NS_ :

BS_:

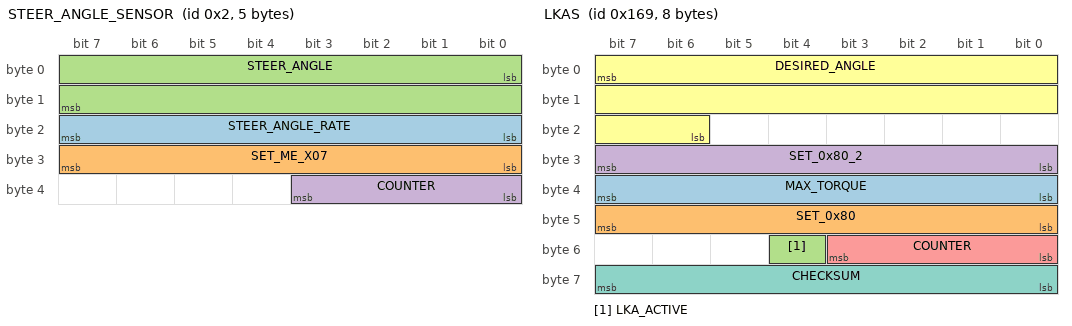
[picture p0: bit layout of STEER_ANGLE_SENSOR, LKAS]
BO_ 2 STEER_ANGLE_SENSOR: 5 XXX
 SG_ STEER_ANGLE_RATE : 16|8@1+ (1,0) [0|255] "" XXX
 SG_ SET_ME_X07 : 24|8@1+ (1,0) [0|255] "" XXX
 SG_ STEER_ANGLE : 0|16@1- (-0.1,0) [0|65535] "" XXX
 SG_ COUNTER : 32|4@1+ (1,0) [0|15] "" XXX

BO_ 361 LKAS: 8 XXX
 SG_ MAX_TORQUE : 39|8@0+ (0.01,0) [0|255] "Nm" XXX
 SG_ SET_0x80 : 47|8@0+ (1,0) [0|255] "" XXX
 SG_ LKA_ACTIVE : 52|1@0+ (1,0) [0|15] "" XXX
 SG_ SET_0x80_2 : 31|8@0+ (1,0) [0|255] "" XXX
 SG_ COUNTER : 51|4@0+ (1,0) [0|15] "" XXX
 SG_ DESIRED_ANGLE : 7|18@0+ (-0.01,1310) [-1311.43|1310] "" XXX
 SG_ CHECKSUM : 63|8@0+ (1,0) [0|255] "" XXX

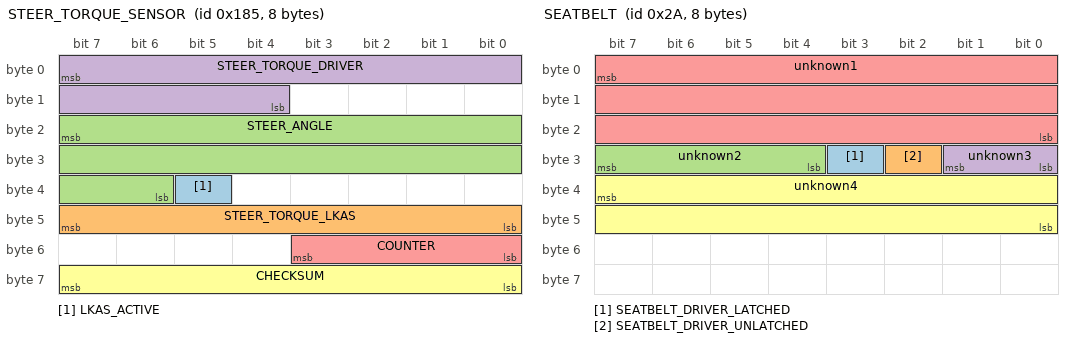
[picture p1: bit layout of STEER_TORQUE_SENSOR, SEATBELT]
BO_ 389 STEER_TORQUE_SENSOR: 8 XXX
 SG_ LKAS_ACTIVE : 37|1@0+ (1,0) [0|3] "" XXX
 SG_ STEER_TORQUE_LKAS : 47|8@0+ (1,0) [0|255] "" XXX
 SG_ STEER_ANGLE : 23|18@0+ (-0.01,1310) [0|262143] "" XXX
 SG_ STEER_TORQUE_DRIVER : 7|12@0+ (-0.01,20.47) [0|4095] "Nm" XXX
 SG_ COUNTER : 51|4@0+ (1,0) [0|15] "" XXX
 SG_ CHECKSUM : 63|8@0+ (1,0) [0|127] "" XXX

BO_ 645 WHEEL_SPEEDS_REAR: 8 XXX
 SG_ WHEEL_SPEED_RR : 7|16@0+ (0.005,0) [0|65535] "KPH" XXX
 SG_ WHEEL_SPEED_RL : 23|16@0+ (0.005,0) [0|65535] "KPH" XXX

BO_ 689 PROPILOT_HUD: 8 XXX
 SG_ LARGE_WARNING_FLASHING : 9|1@0+ (1,0) [0|1] "" XXX
 SG_ SIDE_RADAR_ERROR_FLASHING1 : 10|1@0+ (1,0) [0|1] "" XXX
 SG_ SIDE_RADAR_ERROR_FLASHING2 : 11|1@0+ (1,0) [0|1] "" XXX
 SG_ RIGHT_LANE_YELLOW_FLASH : 12|1@0+ (1,0) [0|1] "" XXX
 SG_ LEFT_LANE_YELLOW_FLASH : 13|1@0+ (1,0) [0|1] "" XXX
 SG_ LEAD_CAR : 14|1@0+ (1,0) [0|1] "" XXX
 SG_ LEAD_CAR_ERROR : 15|1@0+ (1,0) [0|1] "" XXX
 SG_ FRONT_RADAR_ERROR : 16|1@0+ (1,0) [0|1] "" XXX
 SG_ FRONT_RADAR_ERROR_FLASHING : 17|1@0+ (1,0) [0|1] "" XXX
 SG_ RIGHT_LANE_GREEN : 24|1@0+ (1,0) [0|1] "" XXX
 SG_ LEFT_LANE_GREEN : 25|1@0+ (1,0) [0|1] "" XXX
 SG_ SIDE_RADAR_ERROR_FLASHING3 : 27|1@0+ (1,0) [0|1] "" XXX
 SG_ LKAS_ERROR_FLASHING : 29|1@0+ (1,0) [0|1] "" XXX
 SG_ SAFETY_SHIELD_ACTIVE : 44|1@0+ (1,0) [0|1] "" XXX
 SG_ LARGE_STEERING_WHEEL_ICON : 61|2@0+ (1,0) [0|3] "" XXX
 SG_ RIGHT_LANE_GREEN_FLASH : 62|1@0+ (1,0) [0|1] "" XXX
 SG_ LEFT_LANE_GREEN_FLASH : 63|1@0+ (1,0) [0|1] "" XXX
 SG_ FOLLOW_DISTANCE : 3|2@0+ (1,0) [0|3] "" XXX
 SG_ AUDIBLE_TONE : 47|3@0+ (1,0) [0|8] "" XXX
 SG_ SPEED_SET_ICON : 7|2@0+ (1,0) [0|3] "" XXX
 SG_ SMALL_STEERING_WHEEL_ICON : 42|3@0+ (1,0) [0|7] "" XXX
 SG_ SET_SPEED : 39|8@0+ (1,0) [0|255] "" XXX
 SG_ unknown02 : 1|2@0+ (1,0) [0|3] "" XXX
 SG_ unknown05 : 5|2@0+ (1,0) [0|3] "" XXX
 SG_ unknown08 : 8|7@0+ (1,0) [0|63] "" XXX
 SG_ unknown26 : 26|1@0+ (1,0) [0|1] "" XXX
 SG_ unknown28 : 28|1@0+ (1,0) [0|1] "" XXX
 SG_ unknown31 : 31|2@0+ (1,0) [0|3] "" XXX
 SG_ unknown43 : 43|1@0+ (1,0) [0|1] "" XXX
 SG_ unknown55 : 55|8@0+ (1,0) [0|63] "" XXX
 SG_ unknown59 : 59|4@0+ (1,0) [0|15] "" XXX

BO_ 783 CRUISE_STATE: 3 XXX
 SG_ CRUISE_ENABLED : 3|1@0+ (1,0) [0|1] "" XXX

BO_ 1228 PROPILOT_HUD_INFO_MSG: 8 XXX
 SG_ NA_HIGH_ACCEL_TEMP : 0|1@0+ (1,0) [0|1] "" XXX
 SG_ SIDE_RADAR_NA_HIGH_CABIN_TEMP : 8|1@0+ (1,0) [0|1] "" XXX
 SG_ SIDE_RADAR_MALFUNCTION : 11|1@0+ (1,0) [0|1] "" XXX
 SG_ LKAS_MALFUNCTION : 12|1@0+ (1,0) [0|1] "" XXX
 SG_ FRONT_RADAR_MALFUNCTION : 13|1@0+ (1,0) [0|1] "" XXX
 SG_ SIDE_RADAR_NA_CLEAN_REAR_CAMERA : 14|1@0+ (1,0) [0|1] "" XXX
 SG_ NA_POOR_ROAD_CONDITIONS : 16|1@0+ (1,0) [0|1] "" XXX
 SG_ CURRENTLY_UNAVAILABLE : 17|1@0+ (1,0) [0|1] "" XXX
 SG_ SAFETY_SHIELD_OFF : 18|1@0+ (1,0) [0|1] "" XXX
 SG_ FRONT_COLLISION_NA_FRONT_RADAR_OBSTRUCTION : 20|1@0+ (1,0) [0|1] "" XXX
 SG_ PEDAL_MISSAPPLICATION_SYSTEM_ACTIVATED : 24|1@0+ (1,0) [0|1] "" XXX
 SG_ SIDE_IMPACT_NA_RADAR_OBSTRUCTION : 25|1@0+ (1,0) [0|1] "" XXX
 SG_ WARNING_DO_NOT_ENTER : 33|1@0+ (1,0) [0|1] "" XXX
 SG_ SIDE_IMPACT_SYSTEM_OFF : 34|1@0+ (1,0) [0|1] "" XXX
 SG_ SIDE_IMPACT_MALFUNCTION : 35|1@0+ (1,0) [0|1] "" XXX
 SG_ FRONT_COLLISION_MALFUNCTION : 36|1@0+ (1,0) [0|1] "" XXX
 SG_ SIDE_RADAR_MALFUNCTION2 : 37|1@0+ (1,0) [0|1] "" XXX
 SG_ LKAS_MALFUNCTION2 : 38|1@0+ (1,0) [0|1] "" XXX
 SG_ FRONT_RADAR_MALFUNCTION2 : 39|1@0+ (1,0) [0|1] "" XXX
 SG_ PROPILOT_NA_MSGS : 42|3@0+ (1,0) [0|7] "" XXX
 SG_ BOTTOM_MSG : 45|3@0+ (1,0) [0|7] "" XXX
 SG_ HANDS_ON_WHEEL_WARNING : 47|1@0+ (1,0) [0|1] "" XXX
 SG_ WARNING_STEP_ON_BRAKE_NOW : 51|1@0+ (1,0) [0|1] "" XXX
 SG_ PROPILOT_NA_FRONT_CAMERA_OBSTRUCTED : 52|1@0+ (1,0) [0|1] "" XXX
 SG_ PROPILOT_NA_HIGH_CABIN_TEMP : 53|1@0+ (1,0) [0|1] "" XXX
 SG_ WARNING_PROPILOT_MALFUNCTION : 54|1@0+ (1,0) [0|3] "" XXX
 SG_ ACC_UNAVAILABLE_HIGH_CABIN_TEMP : 62|1@0+ (1,0) [0|1] "" XXX
 SG_ ACC_NA_FRONT_CAMERA_IMPARED : 63|1@0+ (1,0) [0|1] "" XXX
 SG_ unknown07 : 7|7@0+ (1,0) [0|127] "" XXX
 SG_ unknown10 : 10|2@0+ (1,0) [0|3] "" XXX
 SG_ unknown15 : 15|1@0+ (1,0) [0|1] "" XXX
 SG_ unknown23 : 23|3@0+ (1,0) [0|7] "" XXX
 SG_ unknown19 : 19|1@0+ (1,0) [0|1] "" XXX
 SG_ unknown31 : 31|6@0+ (1,0) [0|63] "" XXX
 SG_ unknown32 : 32|1@0+ (1,0) [0|1] "" XXX
 SG_ unknown46 : 46|1@0+ (1,0) [0|1] "" XXX
 SG_ unknown50 : 50|3@0+ (1,0) [0|7] "" XXX
 SG_ unknown55 : 55|1@0+ (1,0) [0|1] "" XXX
 SG_ unknown61 : 61|6@0+ (1,0) [0|63] "" XXX

BO_ 1227 LKAS_SETTINGS: 8 XXX
 SG_ LKAS_ENABLED : 51|1@0+ (1,0) [0|1] "" XXX

BO_ 42 SEATBELT: 8 XXX
 SG_ SEATBELT_DRIVER_LATCHED : 27|1@1+ (1,0) [0|3] "" XXX
 SG_ SEATBELT_DRIVER_UNLATCHED : 26|1@0+ (1,0) [0|1] "" XXX
 SG_ unknown2 : 31|4@0+ (1,0) [0|15] "" XXX
 SG_ unknown3 : 24|2@1+ (1,0) [0|3] "" XXX
 SG_ unknown1 : 7|24@0+ (1,0) [0|16777215] "" XXX
 SG_ unknown4 : 39|16@0+ (1,0) [0|65535] "" XXX

BO_ 460 BRAKE_PEDAL: 8 XXX
 SG_ BRAKE_PEDAL : 7|8@0+ (1,0) [0|256] "" XXX

BO_ 569 CRUISE_THROTTLE: 8 XXX
 SG_ GAS_PEDAL_INVERTED : 15|8@0+ (1,0) [0|255] "" XXX
 SG_ GAS_PEDAL : 7|8@0+ (1,0) [0|255] "" XXX
 SG_ CRUISE_AVAILABLE : 17|1@0+ (1,0) [0|1] "" XXX
 SG_ unsure1 : 23|6@0+ (1,0) [0|63] "" XXX
 SG_ unsure2 : 16|1@0+ (1,0) [0|1] "" XXX
 SG_ unsure3 : 31|2@0+ (1,0) [0|3] "" XXX
 SG_ NO_BUTTON_PRESSED : 29|1@0+ (1,0) [0|1] "" XXX
 SG_ RES_BUTTON : 28|1@0+ (1,0) [0|1] "" XXX
 SG_ SET_BUTTON : 27|1@0+ (1,0) [0|1] "" XXX
 SG_ FOLLOW_DISTANCE_BUTTON : 26|1@0+ (1,0) [0|1] "" XXX
 SG_ CANCEL_BUTTON : 25|1@0+ (1,0) [0|1] "" XXX
 SG_ PROPILOT_BUTTON : 24|1@0+ (1,0) [0|1] "" XXX
 SG_ USER_BRAKE_PRESSED : 37|1@0+ (1,0) [0|1] "" XXX
 SG_ COUNTER : 32|2@1+ (1,0) [0|3] "" XXX
 SG_ unsure5 : 47|8@0+ (1,0) [0|255] "" XXX
 SG_ unsure6 : 55|8@0+ (1,0) [0|255] "" XXX
 SG_ unsure7 : 63|8@0+ (1,0) [0|255] "" XXX

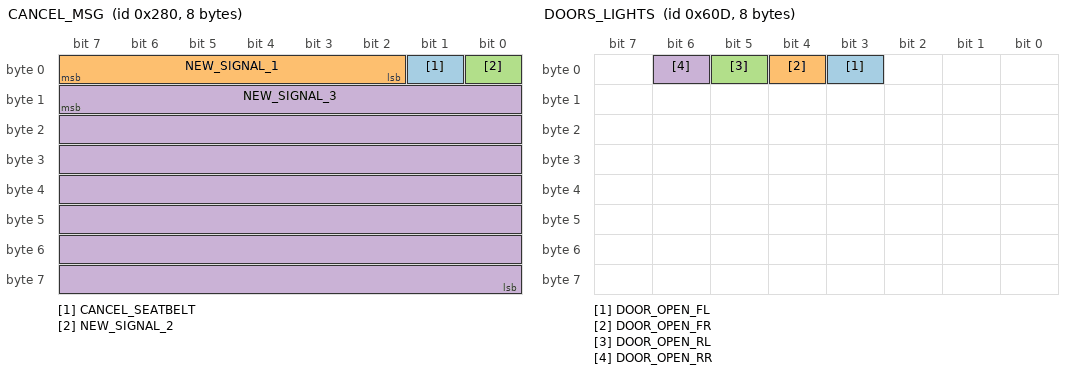
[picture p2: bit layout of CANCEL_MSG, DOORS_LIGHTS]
BO_ 640 CANCEL_MSG: 8 XXX
  SG_ CANCEL_SEATBELT : 1|1@0+ (1,0) [0|1] "" XXX
  SG_ NEW_SIGNAL_1 : 7|6@0+ (1,0) [0|63] "" XXX
  SG_ NEW_SIGNAL_2 : 0|1@0+ (1,0) [0|1] "" XXX
  SG_ NEW_SIGNAL_3 : 15|56@0+ (1,0) [0|72057594037927940] "" XXX

BO_ 644 WHEEL_SPEEDS_FRONT: 8 XXX
 SG_ WHEEL_SPEED_FR : 7|16@0+ (0.005,0) [0|65535] "KPH" XXX
 SG_ WHEEL_SPEED_FL : 23|16@0+ (0.005,0) [0|65535] "KPH" XXX

BO_ 852 ESP: 8 XXX
 SG_ ESP_DISABLED : 38|1@0+ (1,0) [0|1] "" XXX

BO_ 853 HUD_SETTINGS: 8 XXX
 SG_ SPEED_MPH : 37|1@0+ (1,0) [0|1] "" XXX

BO_ 856 LIGHTS: 8 XXX
 SG_ LEFT_BLINKER : 17|1@0+ (1,0) [0|1] "" XXX
 SG_ RIGHT_BLINKER : 18|1@0+ (1,0) [0|1] "" XXX

BO_ 1057 GEARBOX: 3 XXX
 SG_ GEAR_SHIFTER : 5|3@0+ (1,0) [0|255] "" XXX

BO_ 1549 DOORS_LIGHTS: 8 XXX
 SG_ DOOR_OPEN_FL : 3|1@0+ (1,0) [0|1] "" XXX
 SG_ DOOR_OPEN_FR : 4|1@0+ (1,0) [0|1] "" XXX
 SG_ DOOR_OPEN_RL : 5|1@0+ (1,0) [0|1] "" XXX
 SG_ DOOR_OPEN_RR : 6|1@0+ (1,0) [0|1] "" XXX

BU_: ABS ESP ECU TCU SAS

CM_ "AUTOGENERATED FILE, DO NOT EDIT";

CM_ "Imported file _comma.dbc starts here";
CM_ "BO_ STEERING_IPAS_COMMA: Copy of msg 614 so we can do angle control while the Park Assist ECU is connected (Panda spoofs 614 with 359 on connector J70). Note that addresses 0x266 and 0x167 are checksum-invariant";

CM_ "BO_ SECONDARY_STEER_ANGLE: ZSS is a high-precision steering angle sensor that can replace the lower resolution sensor in most TSS1 Toyotas. Learn more: https://github.com/commaai/openpilot/wiki/Toyota-Lexus#zorro-steering-sensor-zss";

CM_ "BO_ SDSU: The sDSU is a modified DSU for use in TSS1 Toyotas. Learn more: https://github.com/wocsor/panda/tree/smart_dsu";
CM_ SG_ 767 FD_BUTTON "The follow distance button signal as forwarded by the sdsu";

CM_ "Imported file _toyota_2017.dbc starts here";
CM_ SG_ 36 YAW_RATE "verify";
CM_ SG_ 36 ACCEL_X "x-axis accel";
CM_ SG_ 37 STEER_FRACTION "1/15th of the signal STEER_ANGLE, which is 1.5 deg; note that 0x8 is never set";
CM_ SG_ 37 STEER_RATE "factor is tbd";
CM_ SG_ 466 NEUTRAL_FORCE "force in newtons the engine/electric motors are applying without any acceleration commands or user input";
CM_ SG_ 466 ACC_BRAKING "whether brakes are being actuated from ACC command";
CM_ SG_ 466 ACCEL_NET "net acceleration produced by the system, given ACCEL_CMD, road grade and other factors";
CM_ SG_ 466 CRUISE_STATE "Active state is 8, if standstill is requested will switch to state 11(3 sec timer), after timer is elapsed will switch into state 7(standstill). If plus button was pressed - status 9, minus button pressed - status 10";
CM_ SG_ 467 ACC_FAULTED "1 when ACC is faulted and the PCM disallows engagement";
CM_ SG_ 467 SET_SPEED "43 km/h are shown as 28 mph, so conversion isn't perfect";
CM_ SG_ 467 LOW_SPEED_LOCKOUT "in low speed lockout, system would always disengage below 28mph";
CM_ SG_ 560 BRAKE_PRESSED "another brake pressed?";
CM_ SG_ 581 GAS_PEDAL "it seems slightly filtered";
CM_ SG_ 608 STEER_TORQUE_DRIVER "driver torque";
CM_ SG_ 608 STEER_OVERRIDE "set when driver torque exceeds a certain value";
CM_ SG_ 614 ANGLE "set to measured angle when ipas control isn't active";
CM_ SG_ 643 _COUNTER "only used on cars that use this msg for cruise control";
CM_ SG_ 643 BRAKE_STATUS "only used on cars that use this msg for cruise control";
CM_ SG_ 643 PRECOLLISION_ACTIVE "set 0.5s before any braking";
CM_ SG_ 835 ACC_TYPE "if 2, car is likely to have a permanent low speed lockout. 1 is ok";
CM_ SG_ 835 RADAR_DIRTY "Display Clean Radar Sensor message on HUD";
CM_ SG_ 835 ACC_MALFUNCTION "display ACC fault on dash if set to 1";
CM_ SG_ 835 ACC_CUT_IN "Display blinking yellow lead if set to 1";
CM_ SG_ 835 DISTANCE "Cycle through ACC following distance from long, mid, short when set to 1";
CM_ SG_ 835 ITS_CONNECT_LEAD "Displayed when lead car is capable of ITS Connect";
CM_ SG_ 835 ALLOW_LONG_PRESS "Enable Toyota's factory set speed increment behaviour, available on both metrics cars and imperial unit cars";
CM_ SG_ 835 PERMIT_BRAKING "Original ACC has this going high when a car in front is detected. In openpilot and before the PERMIT_BRAKING name, this was 'SET_ME_1' and is hardcoded to be high. Unsure if only informational or has an effect though existing usage in openpilot is to always set it to 1. Originally 'PMTBRKG' in the leaked toyota_2017_ref_pt.dbc file and name expansion speculated to be PerMiT BRaKinG.";
CM_ SG_ 835 ACCEL_CMD_ALT "Copy of main ACCEL_CMD, but across 8 bits instead of 16 bits like ACCEL_CMD. Unsure if only informational or has an effect. Likely informational as existing openpilot sets this to 0 and no loss of functionality observed. Originally 'AT_RAW' in leaked toyota_2017_ref_pt.dbc file.";
CM_ SG_ 865 GAS_PEDAL_ALT "copy of main GAS_PEDAL. Both use 8 bits. Might indicate that this message is for pedals.";
CM_ SG_ 865 CLUTCH_RELEASED "boolean of clutch for 6MT.";
CM_ SG_ 865 ACC_FAULTED "1 when ACC is faulted and the PCM disallows engagement. Also describes a lockout when the ACC_CONTROL->ACC_MALFUNCTION bit is set.";
CM_ SG_ 921 UI_SET_SPEED "set speed shown in the vehicle's UI with the vehicle's unit";
CM_ SG_ 921 TEMP_ACC_FAULTED "1 when the UI is displaying or playing fault-related alerts or sounds. Also 1 when pressing main on.";
CM_ SG_ 951 BRAKE_LIGHTS_ACC "brake lights when ACC commands decel";
CM_ SG_ 956 GEAR "on 6MT, only R shows.";
CM_ SG_ 1009 UI_SET_SPEED "units seem to be whatever the car is set to";
CM_ SG_ 1041 PCS_INDICATOR "Pre-Collision System Indicator";
CM_ SG_ 1041 PCS_SENSITIVITY "Pre-Collision System Sensitivity";
CM_ SG_ 1041 PCS_DUST "alert: Front Camera Low Visibility Unavailable See Owner's Manual";
CM_ SG_ 1041 PCS_DUST2 "alert: Pre-Collision System Radar Sensor Blocked Unavailable Clean Radar Sensor";
CM_ SG_ 1041 PCS_TEMP "alert: Front Camera Out of Temperature Range Unavailable Wait until Normal Temperature";
CM_ SG_ 1041 PCS_TEMP2 "alert: Pre-Collision System Out of Temperature Range Unavailable See Owner's Manual";
CM_ SG_ 1041 FRD_ADJ "alert: ERROR ADJUSTING FRONT RADAR BEAM";
CM_ SG_ 1042 LDA_SA_TOGGLE "LDA Steering Assist Toggle";
CM_ SG_ 1042 LDW_EXIST "Unclear what this is, it's usually set to 0";
CM_ SG_ 1042 LDA_SENSITIVITY "LDA Sensitivity";
CM_ SG_ 1042 LDA_ON_MESSAGE "Display LDA Turned ON message";
CM_ SG_ 1042 REPEATED_BEEPS "LDA audible warning";
CM_ SG_ 1042 LDA_UNAVAILABLE_QUIET "LDA toggles and sensitivity settings are greyed out if set to 1";
CM_ SG_ 1042 LDA_MESSAGES "Various LDA Messages";
CM_ SG_ 1042 LDA_FRONT_CAMERA_BLOCKED "originally LDAFCVB, LDA related settings are greyed out if set to 1";
CM_ SG_ 1042 TAKE_CONTROL "Please Control Steering Wheel warning";
CM_ SG_ 1042 LANE_SWAY_TOGGLE "Lane Sway Warning System SWS Switch";
CM_ SG_ 1042 LANE_SWAY_WARNING "Lane Sway Warning System Triggered";
CM_ SG_ 1042 LANE_SWAY_FLD "Unknown signal for Lane Sway Warning System, set to 7 on stock system when SWS is enabled, 0 when SWS is disabled";
CM_ SG_ 1042 LANE_SWAY_BUZZER "Similar to TWO_BEEPS";
CM_ SG_ 1042 SET_ME_X01 "empty bit on leaked dbc, always set to 1 during normal operations";
CM_ SG_ 1042 SET_ME_X02 "empty bit on leaked dbc, always set to 2 during normal operations";
CM_ SG_ 1083 STATE "when the dashboard button is pressed, the value changes from zero to non-zero";
CM_ SG_ 1161 SPDVAL1 "Numbers 0-199 is displayed, 200-254 displays circle without number and 255 is for no limit.";
CM_ SG_ 1161 SYNCID1 "counter from 1 to f at 1 Hz";
CM_ SG_ 1161 SPDVAL2 "conditional speed value 70";
CM_ SG_ 1162 SGNNUMP "1 if SPDVAL1 is set, otherwise 0";
CM_ SG_ 1162 SYNCID2 "counter from 1 to f at 1 Hz";
CM_ SG_ 1163 TSREQPD "always 1";
CM_ SG_ 1163 TSRMSW "always 1";
CM_ SG_ 1163 OTSGNNTM "always 3";
CM_ SG_ 1163 NTLVLSPD "always 3";
CM_ SG_ 1163 OVSPNTM "always 3";
CM_ SG_ 1163 OVSPVALL "-5 at start then 2 after 2 seconds";
CM_ SG_ 1163 OVSPVALM "-5 at start then 5 after 2 seconds";
CM_ SG_ 1163 OVSPVALH "-5 at start then 10 after 2 seconds";
CM_ SG_ 1163 TSRSPU "always 1";
CM_ SG_ 1552 UI_SPEED "Does not appear to match dash";
CM_ SG_ 1552 METER_SLIDER_BRIGHTNESS_PCT "Combination display brightness setting, scales from 12 per cent to 100 per cent, reflects combination meter settings only, not linked with headlight state";
CM_ SG_ 1552 METER_SLIDER_LOW_BRIGHTNESS "Combination display low brightness mode, also controls footwell lighting";
CM_ SG_ 1552 METER_SLIDER_DIMMED "Combination display slider not at max, reflects combination meter settings only, not linked with headlight state";
CM_ SG_ 1553 ODOMETER "Unit is dependent upon units signal";
CM_ SG_ 1592 LOCK_STATUS_CHANGED "1 on rising edge of lock/unlocking";
CM_ SG_ 1592 LOCK_STATUS "The next 3 bits always seem to follow this signal.";
CM_ SG_ 1592 LOCKED_VIA_KEYFOB "1 for as long as car is locked with key fob or door handle touch";

CM_ "toyota_new_mc_pt.dbc starts here";

CM_ SG_ 548 BRAKE_PRESSURE "seems prop to pedal force";
CM_ SG_ 548 BRAKE_POSITION "seems proportional to pedal displacement, unclear the max value of 0x1c8";
CM_ SG_ 610 TYPE "seems 1 on Corolla, 0 on all others";
